# CH583SFR register map
Vendor: WCH Ltd.; Series: CH58x; File version: 1.0
CPU: RISC-V r0p0, little endian, no MPU, no FPU, 2 interrupt priority bits
Registers are 8-bit, read-write, reset 0x0 unless marked. A register's access mark holds for its fields unless they carry their own. Offsets are from the block's base; [hi:lo] are bit positions; {n}, {i} and the like mark numbered series; 'fields as' and 'values as' point back to an identical list.

## USB2
Base 0x40008400
0x00 R8_USB2_CTRL reset 0x6 — USB2 base control
  [7] RB_UC_HOST_MODE — enable USB host mode: 0=device mode, 1=host mode
  [6] RB_UC_LOW_SPEED — enable USB low speed: 0=12Mbps, 1=1.5Mbps
  [5] RB_UC_DEV_PU_EN — USB device enable and internal pullup resistance enable
  [5:4] MASK_UC_SYS_CTRL — bit mask of USB system control
  [3] RB_UC_INT_BUSY — enable automatic responding busy for device mode or automatic pause for host mode during interrupt flag UIF_TRANSFER valid
  [2] RB_UC_RESET_SIE — force reset USB SIE, need software clear
  [1] RB_UC_CLR_ALL — force clear FIFO and count of USB
  [0] RB_UC_DMA_EN — DMA enable and DMA interrupt enable for USB
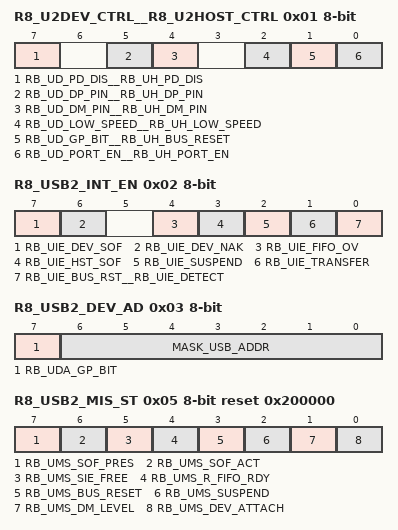
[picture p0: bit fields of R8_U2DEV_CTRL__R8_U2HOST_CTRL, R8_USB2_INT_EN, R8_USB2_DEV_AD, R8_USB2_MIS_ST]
0x01 R8_U2DEV_CTRL__R8_U2HOST_CTRL access per field — USB2 device physical prot control
  [7] RB_UD_PD_DIS__RB_UH_PD_DIS ro — disable USB UDP-UDM pulldown resistance: 0=enable pulldown, 1=disable
  [5] RB_UD_DP_PIN__RB_UH_DP_PIN ro — ReadOnly: indicate current UDP pin level
  [4] RB_UD_DM_PIN__RB_UH_DM_PIN ro — ReadOnly: indicate current UDM pin level
  [2] RB_UD_LOW_SPEED__RB_UH_LOW_SPEED rw — enable USB physical port low speed: 0=full speed, 1=low speed;enable USB port low speed: 0=full speed, 1=low speed
  [1] RB_UD_GP_BIT__RB_UH_BUS_RESET rw — general purpose bit;control USB bus reset: 0=normal, 1=force bus reset
  [0] RB_UD_PORT_EN__RB_UH_PORT_EN rw — enable USB physical port I-O: 0=disable, 1=enable;enable USB port: 0=disable, 1=enable port, automatic disabled if USB device detached
0x02 R8_USB2_INT_EN — USB2 interrupt enable
  [7] RB_UIE_DEV_SOF — enable interrupt for SOF received for USB device mode
  [6] RB_UIE_DEV_NAK — enable interrupt for NAK responded for USB device mode
  [4] RB_UIE_FIFO_OV — enable interrupt for FIFO overflow
  [3] RB_UIE_HST_SOF — enable interrupt for host SOF timer action for USB host mode
  [2] RB_UIE_SUSPEND — enable interrupt for USB suspend or resume event
  [1] RB_UIE_TRANSFER — enable interrupt for USB transfer completion
  [0] RB_UIE_BUS_RST__RB_UIE_DETECT — enable interrupt for USB bus reset event for USB device mode;enable interrupt for USB device detected event for USB host mode
0x03 R8_USB2_DEV_AD — USB2 device address
  [7] RB_UDA_GP_BIT — general purpose bit
  [6:0] MASK_USB_ADDR — bit mask for USB device address
0x05 R8_USB2_MIS_ST ro reset 0x200000 — USB2 miscellaneous status
  [7] RB_UMS_SOF_PRES — RO, indicate host SOF timer presage status
  [6] RB_UMS_SOF_ACT — RO, indicate host SOF timer action status for USB host
  [5] RB_UMS_SIE_FREE — RO, indicate USB SIE free status
  [4] RB_UMS_R_FIFO_RDY — RO, indicate USB receiving FIFO ready status (not empty)
  [3] RB_UMS_BUS_RESET — RO, indicate USB bus reset status
  [2] RB_UMS_SUSPEND — RO, indicate USB suspend status
  [1] RB_UMS_DM_LEVEL — RO, indicate UDM level saved at device attached to USB host
  [0] RB_UMS_DEV_ATTACH — RO, indicate device attached status on USB host
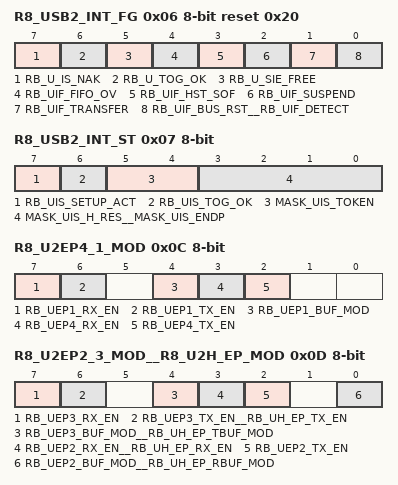
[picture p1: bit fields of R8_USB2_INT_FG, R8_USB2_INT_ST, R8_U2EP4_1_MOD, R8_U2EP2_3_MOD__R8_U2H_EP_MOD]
0x06 R8_USB2_INT_FG reset 0x20 — USB2 interrupt flag
  [7] RB_U_IS_NAK ro — RO, indicate current USB transfer is NAK received
  [6] RB_U_TOG_OK ro — RO, indicate current USB transfer toggle is OK
  [5] RB_U_SIE_FREE ro — RO, indicate USB SIE free status
  [4] RB_UIF_FIFO_OV — RW,FIFO overflow interrupt flag for USB, direct bit address clear or write 1 to clear
  [3] RB_UIF_HST_SOF — RW,host SOF timer interrupt flag for USB host, direct bit address clear or write 1 to clear
  [2] RB_UIF_SUSPEND — RW,USB suspend or resume event interrupt flag, direct bit address clear or write 1 to clear
  [1] RB_UIF_TRANSFER — RW,USB transfer completion interrupt flag, direct bit address clear or write 1 to clear
  [0] RB_UIF_BUS_RST__RB_UIF_DETECT — RW,bus reset event interrupt flag for USB device mode, direct bit address clear or write 1 to clear;device detected event interrupt flag for USB host mode, direct bit address clear or write 1 to clear
0x07 R8_USB2_INT_ST ro — USB2 interrupt status
  [7] RB_UIS_SETUP_ACT — RO, indicate current USB transfer is NAK received for USB device mode
  [6] RB_UIS_TOG_OK — RO, indicate current USB transfer toggle is OK
  [5:4] MASK_UIS_TOKEN — RO, bit mask of current token PID code received for USB device mode
  [3:0] MASK_UIS_H_RES__MASK_UIS_ENDP — RO, bit mask of current transfer handshake response for USB host mode: 0000=no response, time out from device, others=handshake response PID received;RO, bit mask of current transfer endpoint number for USB device mode
0x08 R8_USB2_RX_LEN ro — USB2 receiving length
  [7:0] R8_USB_RX_LEN — RO,USB receiving length
0x0C R8_U2EP4_1_MOD — endpoint 4/1 mode
  [7] RB_UEP1_RX_EN — enable USB endpoint 1 receiving (OUT)
  [6] RB_UEP1_TX_EN — enable USB endpoint 1 transmittal (IN)
  [4] RB_UEP1_BUF_MOD — buffer mode of USB endpoint 1
  [3] RB_UEP4_RX_EN — enable USB endpoint 4 receiving (OUT)
  [2] RB_UEP4_TX_EN — enable USB endpoint 4 transmittal (IN)
0x0D R8_U2EP2_3_MOD__R8_U2H_EP_MOD — endpoint 2_3 mode;host endpoint mode
  [7] RB_UEP3_RX_EN — enable USB endpoint 3 receiving (OUT)
  [6] RB_UEP3_TX_EN__RB_UH_EP_TX_EN — enable USB endpoint 3 transmittal (IN);enable USB host OUT endpoint transmittal
  [4] RB_UEP3_BUF_MOD__RB_UH_EP_TBUF_MOD — buffer mode of USB endpoint 3;buffer mode of USB host OUT endpoint
  [3] RB_UEP2_RX_EN__RB_UH_EP_RX_EN — enable USB endpoint 2 receiving (OUT);enable USB host IN endpoint receiving
  [2] RB_UEP2_TX_EN — enable USB endpoint 2 transmittal (IN)
  [0] RB_UEP2_BUF_MOD__RB_UH_EP_RBUF_MOD — buffer mode of USB endpoint 2;buffer mode of USB host IN endpoint
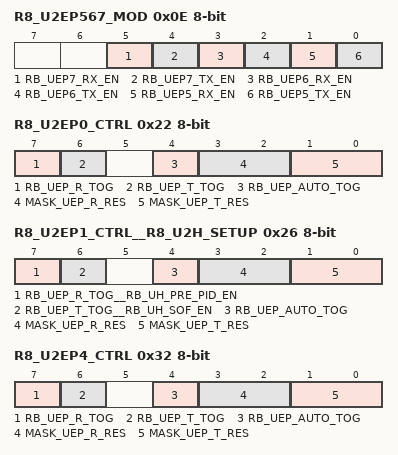
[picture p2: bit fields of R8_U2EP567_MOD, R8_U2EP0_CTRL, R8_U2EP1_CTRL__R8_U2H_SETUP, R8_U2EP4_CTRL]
0x0E R8_U2EP567_MOD — USB2 endpoint 5/6/7 mode
  [5] RB_UEP7_RX_EN — enable USB endpoint 7 receiving (OUT)
  [4] RB_UEP7_TX_EN — enable USB endpoint 7 transmittal (IN)
  [3] RB_UEP6_RX_EN — enable USB endpoint 6 receiving (OUT)
  [2] RB_UEP6_TX_EN — enable USB endpoint 6 transmittal (IN)
  [1] RB_UEP5_RX_EN — enable USB endpoint 5 receiving (OUT)
  [0] RB_UEP5_TX_EN — enable USB endpoint 5 transmittal (IN)
0x10 R16_U2EP0_DMA 16-bit — endpoint 0 DMA buffer address
  [15:0] R16_UEP0_DMA — RW,endpoint 0 DMA buffer address
0x14 R16_U2EP1_DMA 16-bit — USB2 endpoint 1 DMA buffer address
  [15:0] R16_UEP1_DMA — RW,endpoint 1 DMA buffer address
0x18 R16_U2EP2_DMA__R16_U2H_RX_DMA 16-bit — USB2 endpoint 2 DMA buffer address;host rx endpoint buffer high address
  [15:0] R16_UEP2_DMA — RW,endpoint 2 DMA buffer address;host rx endpoint buffer high address
0x1C R16_U2EP3_DMA__R16_U2H_TX_DMA 16-bit — USB2 endpoint 3 DMA buffer address;host tx endpoint buffer high address
  [15:0] R16_UEP3_DMA — RW,endpoint 3 DMA buffer address;host rx endpoint buffer high address
0x20 R8_U2EP0_T_LEN — USB2 endpoint 0 transmittal length
  [7:0] R8_UEP0_T_LEN — endpoint 0 transmittal length
0x22 R8_U2EP0_CTRL — USB2 endpoint 0 control
  [7] RB_UEP_R_TOG — expected data toggle flag of USB endpoint X receiving (OUT): 0=DATA0, 1=DATA1
  [6] RB_UEP_T_TOG — prepared data toggle flag of USB endpoint X transmittal (IN): 0=DATA0, 1=DATA1
  [4] RB_UEP_AUTO_TOG — enable automatic toggle after successful transfer completion on endpoint 1_2_3: 0=manual toggle, 1=automatic toggle
  [3:2] MASK_UEP_R_RES — bit mask of handshake response type for USB endpoint X receiving (OUT)
  [1:0] MASK_UEP_T_RES — bit mask of handshake response type for USB endpoint X transmittal (IN)
0x24 R8_U2EP1_T_LEN — USB2 endpoint 1 transmittal length
  [7:0] R8_UEP1_T_LEN — endpoint 1 transmittal length
0x26 R8_U2EP1_CTRL__R8_U2H_SETUP — USB2 endpoint 1 control;host aux setup
  [7] RB_UEP_R_TOG__RB_UH_PRE_PID_EN — expected data toggle flag of USB endpoint X receiving (OUT): 0=DATA0, 1=DATA1;RB_UH_PRE_PID_EN;USB host PRE PID enable for low speed device via hub
  [6] RB_UEP_T_TOG__RB_UH_SOF_EN — prepared data toggle flag of USB endpoint X transmittal (IN): 0=DATA0, 1=DATA1;USB host automatic SOF enable
  [4] RB_UEP_AUTO_TOG — enable automatic toggle after successful transfer completion on endpoint 1_2_3: 0=manual toggle, 1=automatic toggle
  [3:2] MASK_UEP_R_RES — bit mask of handshake response type for USB endpoint X receiving (OUT)
  [1:0] MASK_UEP_T_RES — bit mask of handshake response type for USB endpoint X transmittal (IN)
0x28 R8_U2EP2_T_LEN_R8_U2H_EP_PID — USB2 endpoint 2 transmittal length;host endpoint and PID
  [7:4] MASK_UH_TOKEN — bit mask of token PID for USB host transfer
  [3:0] MASK_UH_ENDP — bit mask of endpoint number for USB host transfer
  [7:0] R8_UEP2_T_LEN — endpoint 2 transmittal length;
0x2A R8_U2EP2_CTRL_R8_U2H_RX_CTRL — USB2 endpoint 2 control;host receiver endpoint control
  [7] RB_UEP_R_TOG__RB_UH_R_TOG — expected data toggle flag of USB endpoint X receiving (OUT): 0=DATA0, 1=DATA1;expected data toggle flag of host receiving (IN): 0=DATA0, 1=DATA1
  [6] RB_UEP_T_TOG — prepared data toggle flag of USB endpoint X transmittal (IN): 0=DATA0, 1=DATA1
  [4] RB_UEP_AUTO_TOG__RB_UH_R_AUTO_TOG — enable automatic toggle after successful transfer completion on endpoint 1_2_3: 0=manual toggle, 1=automatic toggle;enable automatic toggle after successful transfer completion: 0=manual toggle, 1=automatic toggle
  [2] MASK_UH_R_RES — bit mask of handshake response type for USB endpoint X receiving (OUT)
  [3:2] MASK_UEP_R_RES — bit mask of handshake response type for USB endpoint X receiving (OUT)
  [1:0] MASK_UEP_T_RES — bit mask of handshake response type for USB endpoint X transmittal (IN)
0x2C R8_U2EP3_T_LEN__R8_U2H_TX_LEN — USB2 endpoint 3 transmittal length;host transmittal endpoint transmittal length
  [7:0] R8_UEP3_T_LEN__R8_UH_TX_LEN — endpoint 1 transmittal length
0x2E R8_U2EP3_CTRL__R8_U2H_TX_CTRL — USB2 endpoint 3 control;host transmittal endpoint control
  [7] RB_UEP_R_TOG — expected data toggle flag of USB endpoint X receiving (OUT): 0=DATA0, 1=DATA1
  [6] RB_UEP_T_TOG_RB_UH_T_TOG — prepared data toggle flag of USB endpoint X transmittal (IN): 0=DATA0, 1=DATA1
  [4] RB_UEP_AUTO_TOG_RB_UH_T_AUTO_TOG — enable automatic toggle after successful transfer completion on endpoint 1_2_3: 0=manual toggle, 1=automatic toggle
  [3:2] MASK_UEP_R_RES — bit mask of handshake response type for USB endpoint X receiving (OUT)
  [1:0] RB_UH_T_RES — bit mask of handshake response type for USB endpoint X transmittal (IN)
  [1:0] MASK_UEP_T_RES — bit mask of handshake response type for USB endpoint X transmittal (IN)
0x30 R8_U2EP4_T_LEN — USB2 endpoint 4 transmittal length
  [7:0] R8_UEP4_T_LEN — endpoint 4 transmittal length
0x32 R8_U2EP4_CTRL — USB2 endpoint 4 control
  fields as R8_U2EP0_CTRL
{0x40+4i} R16_U2EP{i}_DMA 16-bit (i=5..7) — USB2 endpoint {i} DMA buffer address
  [15:0] R16_UEP{i}_DMA — RW,endpoint {i} DMA buffer address;host rx endpoint buffer high address
{0x50+4i} R8_U2EP{i}_T_LEN (i=5..7) — USB2 endpoint {i} transmittal length
  [7:0] R8_UEP{i}_T_LEN — endpoint {i} transmittal length
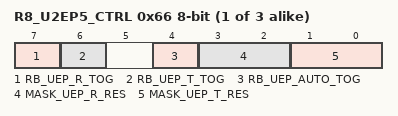
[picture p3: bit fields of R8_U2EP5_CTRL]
{0x52+4i} R8_U2EP{i}_CTRL (i=5..7) — USB2 endpoint {i} control
  fields as R8_U2EP0_CTRL
